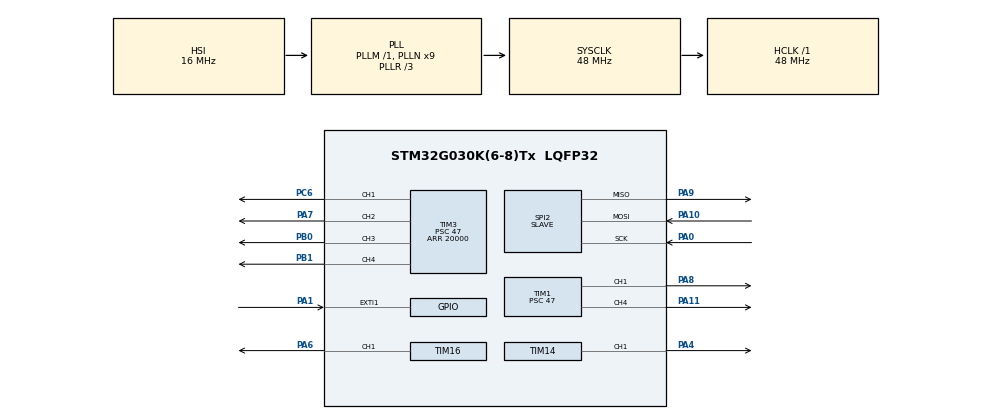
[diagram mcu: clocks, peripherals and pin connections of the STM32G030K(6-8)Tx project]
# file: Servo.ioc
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Dma.Request0=SPI2_RX
Dma.Request1=SPI2_TX
Dma.SPI2_RX.0.Direction=DMA_PERIPH_TO_MEMORY
Dma.SPI2_RX.0.EventEnable=DISABLE
Dma.SPI2_RX.0.Instance=DMA1_Channel1
Dma.SPI2_RX.0.MemDataAlignment=DMA_MDATAALIGN_HALFWORD
Dma.SPI2_RX.0.MemInc=DMA_MINC_ENABLE
Dma.SPI2_RX.0.Mode=DMA_NORMAL
Dma.SPI2_RX.0.PeriphDataAlignment=DMA_PDATAALIGN_HALFWORD
Dma.SPI2_RX.0.PeriphInc=DMA_PINC_DISABLE
Dma.SPI2_RX.0.Polarity=HAL_DMAMUX_REQ_GEN_RISING
Dma.SPI2_RX.0.Priority=DMA_PRIORITY_LOW
Dma.SPI2_RX.0.RequestNumber=1
Dma.SPI2_RX.0.SignalID=NONE
Dma.SPI2_RX.0.SyncEnable=DISABLE
Dma.SPI2_RX.0.SyncPolarity=HAL_DMAMUX_SYNC_NO_EVENT
Dma.SPI2_RX.0.SyncRequestNumber=1
Dma.SPI2_RX.0.SyncSignalID=NONE
Dma.SPI2_TX.1.Direction=DMA_MEMORY_TO_PERIPH
Dma.SPI2_TX.1.EventEnable=DISABLE
Dma.SPI2_TX.1.Instance=DMA1_Channel2
Dma.SPI2_TX.1.MemDataAlignment=DMA_MDATAALIGN_HALFWORD
Dma.SPI2_TX.1.MemInc=DMA_MINC_ENABLE
Dma.SPI2_TX.1.Mode=DMA_NORMAL
Dma.SPI2_TX.1.PeriphDataAlignment=DMA_PDATAALIGN_HALFWORD
Dma.SPI2_TX.1.PeriphInc=DMA_PINC_DISABLE
Dma.SPI2_TX.1.Polarity=HAL_DMAMUX_REQ_GEN_RISING
Dma.SPI2_TX.1.Priority=DMA_PRIORITY_LOW
Dma.SPI2_TX.1.RequestNumber=1
Dma.SPI2_TX.1.SignalID=NONE
Dma.SPI2_TX.1.SyncEnable=DISABLE
Dma.SPI2_TX.1.SyncPolarity=HAL_DMAMUX_SYNC_NO_EVENT
Dma.SPI2_TX.1.SyncRequestNumber=1
Dma.SPI2_TX.1.SyncSignalID=NONE
Mcu.Family=STM32G0
Mcu.Name=STM32G030K(6-8)Tx
Mcu.Package=LQFP32
NVIC.DMA1_Channel1_IRQn=true\:0\:0\:true\:false\:true\:false\:true\:true
NVIC.DMA1_Channel2_3_IRQn=true\:0\:0\:true\:false\:true\:false\:true\:true
NVIC.EXTI0_1_IRQn=true\:0\:0\:false\:false\:true\:true\:true\:true
NVIC.TIM17_IRQn=true\:2\:0\:true\:false\:true\:true\:true\:true
NVIC.TIM1_BRK_UP_TRG_COM_IRQn=true\:3\:0\:true\:false\:true\:true\:true\:true
PA0.Mode=Full_Duplex_Slave
PA0.Signal=SPI2_SCK
PA1.Signal=GPXTI1
PA10.Mode=Full_Duplex_Slave
PA10.Signal=SPI2_MOSI
PA11\ [PA9].Signal=S_TIM1_CH4
PA13.Mode=Serial_Wire
PA13.Signal=SYS_SWDIO
PA14-BOOT0.Mode=Serial_Wire
PA14-BOOT0.Signal=SYS_SWCLK
PA4.Signal=S_TIM14_CH1
PA6.Signal=S_TIM16_CH1
PA7.Signal=S_TIM3_CH2
PA8.Signal=S_TIM1_CH1
PA9.Mode=Full_Duplex_Slave
PA9.Signal=SPI2_MISO
PB0.Signal=S_TIM3_CH3
PB1.Signal=S_TIM3_CH4
PC6.Signal=S_TIM3_CH1
ProjectManager.HeapSize=0x200
ProjectManager.StackSize=0x400
ProjectManager.TargetToolchain=STM32CubeIDE
RCC.ADCFreq_Value=48000000
RCC.AHBFreq_Value=48000000
RCC.CortexFreq_Value=48000000
RCC.EXTERNAL_CLOCK_VALUE=12288000
RCC.HCLKFreq_Value=48000000
RCC.HSE_VALUE=8000000
RCC.HSI_VALUE=16000000
RCC.LSE_VALUE=32768
RCC.PLLN=9
RCC.PLLR=RCC_PLLR_DIV3
RCC.SYSCLKFreq_VALUE=48000000
RCC.SYSCLKSource=RCC_SYSCLKSOURCE_PLLCLK
RCC.VCOOutputFreq_Value=144000000
SH.S_TIM14_CH1.0=TIM14_CH1,PWM Generation1 CH1
SH.S_TIM16_CH1.0=TIM16_CH1,PWM Generation1 CH1
SH.S_TIM1_CH1.0=TIM1_CH1,PWM Generation1 CH1
SH.S_TIM1_CH4.0=TIM1_CH4,PWM Generation4 CH4
SH.S_TIM3_CH1.0=TIM3_CH1,PWM Generation1 CH1
SH.S_TIM3_CH2.0=TIM3_CH2,PWM Generation2 CH2
SH.S_TIM3_CH3.0=TIM3_CH3,PWM Generation3 CH3
SH.S_TIM3_CH4.0=TIM3_CH4,PWM Generation4 CH4
SPI2.CRCCalculation=SPI_CRCCALCULATION_ENABLE
SPI2.DataSize=SPI_DATASIZE_16BIT
SPI2.Direction=SPI_DIRECTION_2LINES
SPI2.Mode=SPI_MODE_SLAVE
SPI2.VirtualType=VM_SLAVE
TIM1.Channel-PWM\ Generation1\ CH1=TIM_CHANNEL_1
TIM1.Channel-PWM\ Generation4\ CH4=TIM_CHANNEL_4
TIM1.Period=20000
TIM1.Prescaler=47
TIM14.Channel=TIM_CHANNEL_1
TIM14.Period=20000
TIM14.Prescaler=47
TIM16.Channel=TIM_CHANNEL_1
TIM16.Period=20000
TIM16.Prescaler=47
TIM17.Period=199
TIM17.Prescaler=47
TIM3.Channel-PWM\ Generation1\ CH1=TIM_CHANNEL_1
TIM3.Channel-PWM\ Generation2\ CH2=TIM_CHANNEL_2
TIM3.Channel-PWM\ Generation3\ CH3=TIM_CHANNEL_3
TIM3.Channel-PWM\ Generation4\ CH4=TIM_CHANNEL_4
TIM3.Period=20000
TIM3.Prescaler=47
VP_TIM14_VS_ClockSourceINT.Mode=Enable_Timer
VP_TIM16_VS_ClockSourceINT.Mode=Enable_Timer
VP_TIM17_VS_ClockSourceINT.Mode=Enable_Timer
VP_TIM1_VS_ClockSourceINT.Mode=Internal
VP_TIM3_VS_ClockSourceINT.Mode=Internal
board=custom

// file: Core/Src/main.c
/* USER CODE BEGIN Header */
/**
  ******************************************************************************
  * @file           : main.c
  * @brief          : Main program body
  ******************************************************************************
  * @attention
  *
  * Copyright (c) 2025 STMicroelectronics.
  * All rights reserved.
  *
  * This software is licensed under terms that can be found in the LICENSE file
  * in the root directory of this software component.
  * If no LICENSE file comes with this software, it is provided AS-IS.
  *
  ******************************************************************************
  */
/* USER CODE END Header */
#include "main.h"

/* USER CODE BEGIN Includes */
void boardInit();
void boardLoop();

/* USER CODE END Includes */

SPI_HandleTypeDef hspi2;
DMA_HandleTypeDef hdma_spi2_rx;
DMA_HandleTypeDef hdma_spi2_tx;

TIM_HandleTypeDef htim1;
TIM_HandleTypeDef htim3;
TIM_HandleTypeDef htim14;
TIM_HandleTypeDef htim16;
TIM_HandleTypeDef htim17;

void SystemClock_Config(void);
static void MX_GPIO_Init(void);
static void MX_DMA_Init(void);
static void MX_TIM3_Init(void);
static void MX_SPI2_Init(void);
static void MX_TIM1_Init(void);
static void MX_TIM14_Init(void);
static void MX_TIM16_Init(void);
static void MX_TIM17_Init(void);

int main(void)
{

  /* MCU Configuration--------------------------------------------------------*/

  /* Reset of all peripherals, Initializes the Flash interface and the Systick. */
  HAL_Init();

  /* Configure the system clock */
  SystemClock_Config();

  /* Initialize all configured peripherals */
  MX_GPIO_Init();
  MX_DMA_Init();
  MX_TIM3_Init();
  MX_SPI2_Init();
  MX_TIM1_Init();
  MX_TIM14_Init();
  MX_TIM16_Init();
  MX_TIM17_Init();

  /* Infinite loop */
  /* USER CODE BEGIN WHILE */
  boardInit();
  while (1)
  {
    /* USER CODE END WHILE */

    /* USER CODE BEGIN 3 */
    boardLoop();
  }
  /* USER CODE END 3 */
}

void SystemClock_Config(void)
{
  RCC_OscInitTypeDef RCC_OscInitStruct = {0};
  RCC_ClkInitTypeDef RCC_ClkInitStruct = {0};

  /** Configure the main internal regulator output voltage
  */
  HAL_PWREx_ControlVoltageScaling(PWR_REGULATOR_VOLTAGE_SCALE1);

  /** Initializes the RCC Oscillators according to the specified parameters
  * in the RCC_OscInitTypeDef structure.
  */
  RCC_OscInitStruct.OscillatorType = RCC_OSCILLATORTYPE_HSI;
  RCC_OscInitStruct.HSIState = RCC_HSI_ON;
  RCC_OscInitStruct.HSIDiv = RCC_HSI_DIV1;
  RCC_OscInitStruct.HSICalibrationValue = RCC_HSICALIBRATION_DEFAULT;
  RCC_OscInitStruct.PLL.PLLState = RCC_PLL_ON;
  RCC_OscInitStruct.PLL.PLLSource = RCC_PLLSOURCE_HSI;
  RCC_OscInitStruct.PLL.PLLM = RCC_PLLM_DIV1;
  RCC_OscInitStruct.PLL.PLLN = 9;
  RCC_OscInitStruct.PLL.PLLP = RCC_PLLP_DIV2;
  RCC_OscInitStruct.PLL.PLLR = RCC_PLLR_DIV3;
  if (HAL_RCC_OscConfig(&RCC_OscInitStruct) != HAL_OK)
  {
    Error_Handler();
  }

  /** Initializes the CPU, AHB and APB buses clocks
  */
  RCC_ClkInitStruct.ClockType = RCC_CLOCKTYPE_HCLK|RCC_CLOCKTYPE_SYSCLK
                              |RCC_CLOCKTYPE_PCLK1;
  RCC_ClkInitStruct.SYSCLKSource = RCC_SYSCLKSOURCE_PLLCLK;
  RCC_ClkInitStruct.AHBCLKDivider = RCC_SYSCLK_DIV1;
  RCC_ClkInitStruct.APB1CLKDivider = RCC_HCLK_DIV1;

  if (HAL_RCC_ClockConfig(&RCC_ClkInitStruct, FLASH_LATENCY_1) != HAL_OK)
  {
    Error_Handler();
  }
}

static void MX_SPI2_Init(void)
{

  /* SPI2 parameter configuration*/
  hspi2.Instance = SPI2;
  hspi2.Init.Mode = SPI_MODE_SLAVE;
  hspi2.Init.Direction = SPI_DIRECTION_2LINES;
  hspi2.Init.DataSize = SPI_DATASIZE_16BIT;
  hspi2.Init.CLKPolarity = SPI_POLARITY_LOW;
  hspi2.Init.CLKPhase = SPI_PHASE_1EDGE;
  hspi2.Init.NSS = SPI_NSS_SOFT;
  hspi2.Init.FirstBit = SPI_FIRSTBIT_MSB;
  hspi2.Init.TIMode = SPI_TIMODE_DISABLE;
  hspi2.Init.CRCCalculation = SPI_CRCCALCULATION_ENABLE;
  hspi2.Init.CRCPolynomial = 7;
  hspi2.Init.CRCLength = SPI_CRC_LENGTH_DATASIZE;
  hspi2.Init.NSSPMode = SPI_NSS_PULSE_DISABLE;
  if (HAL_SPI_Init(&hspi2) != HAL_OK)
  {
    Error_Handler();
  }

}

static void MX_TIM1_Init(void)
{

  TIM_ClockConfigTypeDef sClockSourceConfig = {0};
  TIM_MasterConfigTypeDef sMasterConfig = {0};
  TIM_OC_InitTypeDef sConfigOC = {0};
  TIM_BreakDeadTimeConfigTypeDef sBreakDeadTimeConfig = {0};

  htim1.Instance = TIM1;
  htim1.Init.Prescaler = 47;
  htim1.Init.CounterMode = TIM_COUNTERMODE_UP;
  htim1.Init.Period = 20000;
  htim1.Init.ClockDivision = TIM_CLOCKDIVISION_DIV1;
  htim1.Init.RepetitionCounter = 0;
  htim1.Init.AutoReloadPreload = TIM_AUTORELOAD_PRELOAD_DISABLE;
  if (HAL_TIM_Base_Init(&htim1) != HAL_OK)
  {
    Error_Handler();
  }
  sClockSourceConfig.ClockSource = TIM_CLOCKSOURCE_INTERNAL;
  if (HAL_TIM_ConfigClockSource(&htim1, &sClockSourceConfig) != HAL_OK)
  {
    Error_Handler();
  }
  if (HAL_TIM_PWM_Init(&htim1) != HAL_OK)
  {
    Error_Handler();
  }
  sMasterConfig.MasterOutputTrigger = TIM_TRGO_RESET;
  sMasterConfig.MasterOutputTrigger2 = TIM_TRGO2_RESET;
  sMasterConfig.MasterSlaveMode = TIM_MASTERSLAVEMODE_DISABLE;
  if (HAL_TIMEx_MasterConfigSynchronization(&htim1, &sMasterConfig) != HAL_OK)
  {
    Error_Handler();
  }
  sConfigOC.OCMode = TIM_OCMODE_PWM1;
  sConfigOC.Pulse = 0;
  sConfigOC.OCPolarity = TIM_OCPOLARITY_HIGH;
  sConfigOC.OCNPolarity = TIM_OCNPOLARITY_HIGH;
  sConfigOC.OCFastMode = TIM_OCFAST_DISABLE;
  sConfigOC.OCIdleState = TIM_OCIDLESTATE_RESET;
  sConfigOC.OCNIdleState = TIM_OCNIDLESTATE_RESET;
  if (HAL_TIM_PWM_ConfigChannel(&htim1, &sConfigOC, TIM_CHANNEL_1) != HAL_OK)
  {
    Error_Handler();
  }
  if (HAL_TIM_PWM_ConfigChannel(&htim1, &sConfigOC, TIM_CHANNEL_4) != HAL_OK)
  {
    Error_Handler();
  }
  sBreakDeadTimeConfig.OffStateRunMode = TIM_OSSR_DISABLE;
  sBreakDeadTimeConfig.OffStateIDLEMode = TIM_OSSI_DISABLE;
  sBreakDeadTimeConfig.LockLevel = TIM_LOCKLEVEL_OFF;
  sBreakDeadTimeConfig.DeadTime = 0;
  sBreakDeadTimeConfig.BreakState = TIM_BREAK_DISABLE;
  sBreakDeadTimeConfig.BreakPolarity = TIM_BREAKPOLARITY_HIGH;
  sBreakDeadTimeConfig.BreakFilter = 0;
  sBreakDeadTimeConfig.BreakAFMode = TIM_BREAK_AFMODE_INPUT;
  sBreakDeadTimeConfig.Break2State = TIM_BREAK2_DISABLE;
  sBreakDeadTimeConfig.Break2Polarity = TIM_BREAK2POLARITY_HIGH;
  sBreakDeadTimeConfig.Break2Filter = 0;
  sBreakDeadTimeConfig.Break2AFMode = TIM_BREAK_AFMODE_INPUT;
  sBreakDeadTimeConfig.AutomaticOutput = TIM_AUTOMATICOUTPUT_DISABLE;
  if (HAL_TIMEx_ConfigBreakDeadTime(&htim1, &sBreakDeadTimeConfig) != HAL_OK)
  {
    Error_Handler();
  }
  HAL_TIM_MspPostInit(&htim1);

}

static void MX_TIM3_Init(void)
{

  TIM_ClockConfigTypeDef sClockSourceConfig = {0};
  TIM_MasterConfigTypeDef sMasterConfig = {0};
  TIM_OC_InitTypeDef sConfigOC = {0};

  htim3.Instance = TIM3;
  htim3.Init.Prescaler = 47;
  htim3.Init.CounterMode = TIM_COUNTERMODE_UP;
  htim3.Init.Period = 20000;
  htim3.Init.ClockDivision = TIM_CLOCKDIVISION_DIV1;
  htim3.Init.AutoReloadPreload = TIM_AUTORELOAD_PRELOAD_DISABLE;
  if (HAL_TIM_Base_Init(&htim3) != HAL_OK)
  {
    Error_Handler();
  }
  sClockSourceConfig.ClockSource = TIM_CLOCKSOURCE_INTERNAL;
  if (HAL_TIM_ConfigClockSource(&htim3, &sClockSourceConfig) != HAL_OK)
  {
    Error_Handler();
  }
  if (HAL_TIM_PWM_Init(&htim3) != HAL_OK)
  {
    Error_Handler();
  }
  sMasterConfig.MasterOutputTrigger = TIM_TRGO_RESET;
  sMasterConfig.MasterSlaveMode = TIM_MASTERSLAVEMODE_DISABLE;
  if (HAL_TIMEx_MasterConfigSynchronization(&htim3, &sMasterConfig) != HAL_OK)
  {
    Error_Handler();
  }
  sConfigOC.OCMode = TIM_OCMODE_PWM1;
  sConfigOC.Pulse = 0;
  sConfigOC.OCPolarity = TIM_OCPOLARITY_HIGH;
  sConfigOC.OCFastMode = TIM_OCFAST_DISABLE;
  if (HAL_TIM_PWM_ConfigChannel(&htim3, &sConfigOC, TIM_CHANNEL_1) != HAL_OK)
  {
    Error_Handler();
  }
  if (HAL_TIM_PWM_ConfigChannel(&htim3, &sConfigOC, TIM_CHANNEL_2) != HAL_OK)
  {
    Error_Handler();
  }
  if (HAL_TIM_PWM_ConfigChannel(&htim3, &sConfigOC, TIM_CHANNEL_3) != HAL_OK)
  {
    Error_Handler();
  }
  if (HAL_TIM_PWM_ConfigChannel(&htim3, &sConfigOC, TIM_CHANNEL_4) != HAL_OK)
  {
    Error_Handler();
  }
  HAL_TIM_MspPostInit(&htim3);

}

static void MX_TIM14_Init(void)
{

  TIM_OC_InitTypeDef sConfigOC = {0};

  htim14.Instance = TIM14;
  htim14.Init.Prescaler = 47;
  htim14.Init.CounterMode = TIM_COUNTERMODE_UP;
  htim14.Init.Period = 20000;
  htim14.Init.ClockDivision = TIM_CLOCKDIVISION_DIV1;
  htim14.Init.AutoReloadPreload = TIM_AUTORELOAD_PRELOAD_DISABLE;
  if (HAL_TIM_Base_Init(&htim14) != HAL_OK)
  {
    Error_Handler();
  }
  if (HAL_TIM_PWM_Init(&htim14) != HAL_OK)
  {
    Error_Handler();
  }
  sConfigOC.OCMode = TIM_OCMODE_PWM1;
  sConfigOC.Pulse = 0;
  sConfigOC.OCPolarity = TIM_OCPOLARITY_HIGH;
  sConfigOC.OCFastMode = TIM_OCFAST_DISABLE;
  if (HAL_TIM_PWM_ConfigChannel(&htim14, &sConfigOC, TIM_CHANNEL_1) != HAL_OK)
  {
    Error_Handler();
  }
  HAL_TIM_MspPostInit(&htim14);

}

static void MX_TIM16_Init(void)
{

  TIM_OC_InitTypeDef sConfigOC = {0};
  TIM_BreakDeadTimeConfigTypeDef sBreakDeadTimeConfig = {0};

  htim16.Instance = TIM16;
  htim16.Init.Prescaler = 47;
  htim16.Init.CounterMode = TIM_COUNTERMODE_UP;
  htim16.Init.Period = 20000;
  htim16.Init.ClockDivision = TIM_CLOCKDIVISION_DIV1;
  htim16.Init.RepetitionCounter = 0;
  htim16.Init.AutoReloadPreload = TIM_AUTORELOAD_PRELOAD_DISABLE;
  if (HAL_TIM_Base_Init(&htim16) != HAL_OK)
  {
    Error_Handler();
  }
  if (HAL_TIM_PWM_Init(&htim16) != HAL_OK)
  {
    Error_Handler();
  }
  sConfigOC.OCMode = TIM_OCMODE_PWM1;
  sConfigOC.Pulse = 0;
  sConfigOC.OCPolarity = TIM_OCPOLARITY_HIGH;
  sConfigOC.OCNPolarity = TIM_OCNPOLARITY_HIGH;
  sConfigOC.OCFastMode = TIM_OCFAST_DISABLE;
  sConfigOC.OCIdleState = TIM_OCIDLESTATE_RESET;
  sConfigOC.OCNIdleState = TIM_OCNIDLESTATE_RESET;
  if (HAL_TIM_PWM_ConfigChannel(&htim16, &sConfigOC, TIM_CHANNEL_1) != HAL_OK)
  {
    Error_Handler();
  }
  sBreakDeadTimeConfig.OffStateRunMode = TIM_OSSR_DISABLE;
  sBreakDeadTimeConfig.OffStateIDLEMode = TIM_OSSI_DISABLE;
  sBreakDeadTimeConfig.LockLevel = TIM_LOCKLEVEL_OFF;
  sBreakDeadTimeConfig.DeadTime = 0;
  sBreakDeadTimeConfig.BreakState = TIM_BREAK_DISABLE;
  sBreakDeadTimeConfig.BreakPolarity = TIM_BREAKPOLARITY_HIGH;
  sBreakDeadTimeConfig.BreakFilter = 0;
  sBreakDeadTimeConfig.AutomaticOutput = TIM_AUTOMATICOUTPUT_DISABLE;
  if (HAL_TIMEx_ConfigBreakDeadTime(&htim16, &sBreakDeadTimeConfig) != HAL_OK)
  {
    Error_Handler();
  }
  HAL_TIM_MspPostInit(&htim16);

}

static void MX_TIM17_Init(void)
{

  htim17.Instance = TIM17;
  htim17.Init.Prescaler = 47;
  htim17.Init.CounterMode = TIM_COUNTERMODE_UP;
  htim17.Init.Period = 199;
  htim17.Init.ClockDivision = TIM_CLOCKDIVISION_DIV1;
  htim17.Init.RepetitionCounter = 0;
  htim17.Init.AutoReloadPreload = TIM_AUTORELOAD_PRELOAD_DISABLE;
  if (HAL_TIM_Base_Init(&htim17) != HAL_OK)
  {
    Error_Handler();
  }

}

static void MX_DMA_Init(void)
{

  /* DMA controller clock enable */
  __HAL_RCC_DMA1_CLK_ENABLE();

  /* DMA interrupt init */
  /* DMA1_Channel1_IRQn interrupt configuration */
  HAL_NVIC_SetPriority(DMA1_Channel1_IRQn, 0, 0);
  HAL_NVIC_EnableIRQ(DMA1_Channel1_IRQn);
  /* DMA1_Channel2_3_IRQn interrupt configuration */
  HAL_NVIC_SetPriority(DMA1_Channel2_3_IRQn, 0, 0);
  HAL_NVIC_EnableIRQ(DMA1_Channel2_3_IRQn);

}

static void MX_GPIO_Init(void)
{
  GPIO_InitTypeDef GPIO_InitStruct = {0};

  /* GPIO Ports Clock Enable */
  __HAL_RCC_GPIOA_CLK_ENABLE();
  __HAL_RCC_GPIOB_CLK_ENABLE();
  __HAL_RCC_GPIOC_CLK_ENABLE();

  /*Configure GPIO pin : PA1 */
  GPIO_InitStruct.Pin = GPIO_PIN_1;
  GPIO_InitStruct.Mode = GPIO_MODE_IT_RISING;
  GPIO_InitStruct.Pull = GPIO_NOPULL;
  HAL_GPIO_Init(GPIOA, &GPIO_InitStruct);

  /* EXTI interrupt init*/
  HAL_NVIC_SetPriority(EXTI0_1_IRQn, 0, 0);
  HAL_NVIC_EnableIRQ(EXTI0_1_IRQn);

}

void Error_Handler(void)
{
  __disable_irq();
  while (1)
  {
  }
}
